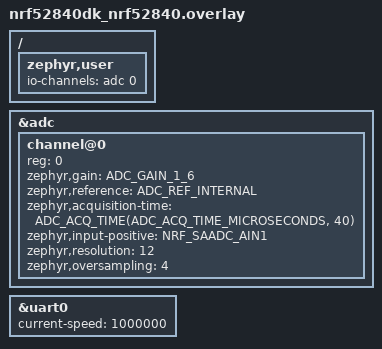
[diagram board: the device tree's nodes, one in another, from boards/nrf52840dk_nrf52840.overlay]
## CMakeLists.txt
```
cmake_minimum_required(VERSION 3.20.0)

set(DTC_OVERLAY_FILE "${CMAKE_CURRENT_SOURCE_DIR}/boards/nrf52840dk_nrf52840.overlay")

find_package(Zephyr REQUIRED HINTS $ENV{ZEPHYR_BASE})

project(heart-rate-monitor)

# Application sources
target_sources(app PRIVATE src/main.c)
```

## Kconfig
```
# Copyright (c) 2021 Nordic Semiconductor ASA
# SPDX-License-Identifier: Apache-2.0
#
# This file is the application Kconfig entry point. All application Kconfig
# options can be defined here or included via other application Kconfig files.
# You can browse these options using the west targets menuconfig (terminal) or
# guiconfig (GUI).

menu "Zephyr"
source "Kconfig.zephyr"
endmenu

module = APP
module-str = APP
source "subsys/logging/Kconfig.template.log_config"

# Application libraries
rsource "../lib/xd58c/Kconfig"
```

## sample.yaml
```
# This file is provided so that the application can be compiled using Twister,
# the Zephyr testing tool. In this file, multiple combinations can be specified,
# so that you can easily test all of them locally or in CI.
sample:
  description: Heart Rate Monitor application with ADC and XD58C support
  name: heart-rate-monitor
common:
  sysbuild: true
  build_only: true
  integration_platforms:
    - nrf52840dk/nrf52840
tests:
  app.default: {}
  app.debug:
    extra_overlay_confs:
      - debug.conf
```

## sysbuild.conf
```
SB_CONFIG_BOOTLOADER_MCUBOOT=y
SB_CONFIG_BOOT_SIGNATURE_KEY_FILE="/workdir/heart-rate-monitor/keys/heart-rate-ec-p256-dev.pem"
```

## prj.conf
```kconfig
# Copyright (c) 2021 Nordic Semiconductor ASA
# SPDX-License-Identifier: Apache-2.0
#
# This file contains selected Kconfig options for the application.

# MCUBOOT and DFU Configuration
CONFIG_BOOTLOADER_MCUBOOT=y
CONFIG_IMG_MANAGER=y
CONFIG_MCUBOOT_IMG_MANAGER=y
CONFIG_MCUBOOT_BOOTUTIL_LIB=y
CONFIG_FLASH=y
CONFIG_FLASH_MAP=y
CONFIG_STREAM_FLASH=y

# Enable logging via RTT, and use deferred logging to minimize the impact on the application's performance.
CONFIG_LOG=y
CONFIG_LOG_BACKEND_UART=n
CONFIG_LOG_MODE_DEFERRED=y
CONFIG_USE_SEGGER_RTT=y
CONFIG_LOG_BACKEND_RTT=y
CONFIG_RTT_CONSOLE=y

CONFIG_UART_CONSOLE=n        # don't redirect printk to UART either
CONFIG_SERIAL=y
CONFIG_UART_NRFX=y
CONFIG_UART_INTERRUPT_DRIVEN=n
CONFIG_UART_ASYNC_API=y

CONFIG_ADC=y
CONFIG_ADC_ASYNC=y

CONFIG_XD58C=y

CONFIG_MAIN_STACK_SIZE=2048
```

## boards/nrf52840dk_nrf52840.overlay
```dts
/*
 * SPDX-License-Identifier: Apache-2.0
 */

/ {
	zephyr,user {
		io-channels = <&adc 0>;
	};
};

&adc {
	#address-cells = <1>;
	#size-cells = <0>;
	status = "okay";
	channel@0 {
		reg = <0>;
		zephyr,gain = "ADC_GAIN_1_6";
		zephyr,reference = "ADC_REF_INTERNAL";
		zephyr,acquisition-time = <ADC_ACQ_TIME(ADC_ACQ_TIME_MICROSECONDS, 40)>;
		zephyr,input-positive = <NRF_SAADC_AIN1>; 
		zephyr,resolution = <12>;
		zephyr,oversampling = <4>;
	};
};

&uart0 {
	current-speed = <1000000>;
};
```

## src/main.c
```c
/*
 * SPDX-License-Identifier: Apache-2.0
 */

#include <app_version.h>
#include <lib/xd58c.h>
#include <zephyr/kernel.h>
#include <zephyr/logging/log.h>

LOG_MODULE_REGISTER(main, LOG_LEVEL_INF);

int main(void) {
  LOG_INF("Heart Rate Monitor %s", APP_VERSION_STRING);

  int err = xd58c_init();
  if (err) {
    LOG_ERR("init XD58C (err %d)", err);
    return err;
  }

  while (1) {
    xd58c_process();
  }

  return 0;
}
```
